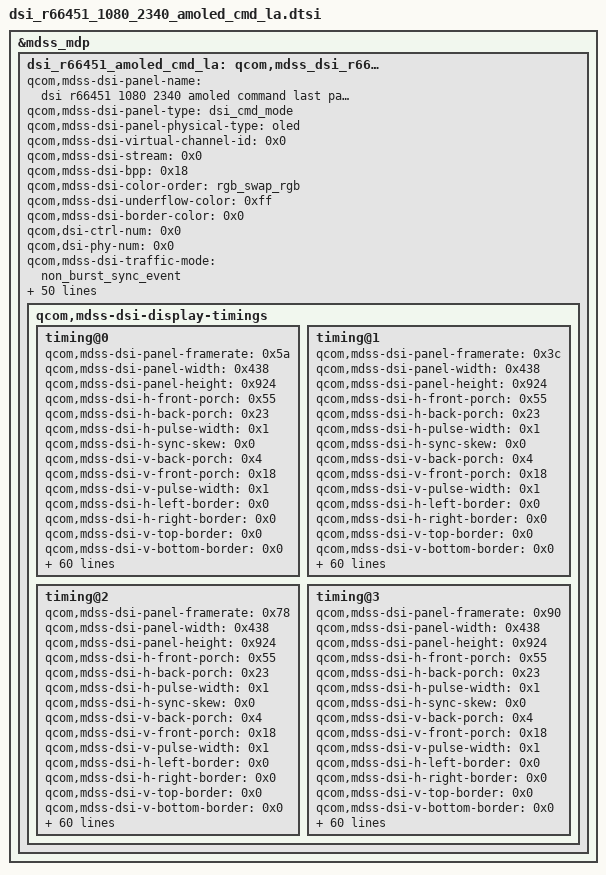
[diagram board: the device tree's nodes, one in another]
/* Copyright (c) 2020, Nubia Technology Co., Ltd. All rights reserved.
 *
 * 从官方 NX651J boot.img 的 dtb 区反编译还原。
 * 这是 "last panel"（末版面板）配置，开源包 dts 中缺失。
 * 官方 release 的 lito/orchid overlay 均包含此节点（每个 +13149 字节）：
 *   官方 dtbo #14 lito-v2-mtp = 281693 字节 vs 开源包 268544 字节
 */

&mdss_mdp {
	dsi_r66451_amoled_cmd_la: qcom,mdss_dsi_r66451_1080_2340_amoled_cmd_la {
		qcom,mdss-dsi-panel-name = "dsi r66451 1080 2340 amoled command last panel";
		qcom,mdss-dsi-panel-type = "dsi_cmd_mode";
		qcom,mdss-dsi-panel-physical-type = "oled";
		qcom,mdss-dsi-virtual-channel-id = <0x0>;
		qcom,mdss-dsi-stream = <0x0>;
		qcom,mdss-dsi-bpp = <0x18>;
		qcom,mdss-dsi-color-order = "rgb_swap_rgb";
		qcom,mdss-dsi-underflow-color = <0xff>;
		qcom,mdss-dsi-border-color = <0x0>;
		qcom,dsi-ctrl-num = <0x0>;
		qcom,dsi-phy-num = <0x0>;
		qcom,mdss-dsi-traffic-mode = "non_burst_sync_event";
		qcom,mdss-dsi-lane-map = "lane_map_0123";
		qcom,mdss-dsi-bllp-eof-power-mode;
		qcom,mdss-dsi-bllp-power-mode;
		qcom,mdss-dsi-lane-0-state;
		qcom,mdss-dsi-lane-1-state;
		qcom,mdss-dsi-lane-2-state;
		qcom,mdss-dsi-lane-3-state;
		qcom,mdss-dsi-dma-trigger = "trigger_sw";
		qcom,mdss-dsi-mdp-trigger = "none";
		qcom,mdss-dsi-reset-sequence = <0x1 0xa 0x0 0xa 0x1 0xa>;
		qcom,mdss-dsi-bl-pmic-control-type = "bl_ctrl_dcs";
		qcom,mdss-dsi-bl-min-level = <0x2d>;
		qcom,mdss-dsi-bl-max-level = <0xfff>;
		qcom,mdss-brightness-max-level = <0xfff>;
		qcom,mdss-dsi-te-pin-select = <0x1>;
		qcom,mdss-dsi-wr-mem-start = <0x2c>;
		qcom,mdss-dsi-wr-mem-continue = <0x3c>;
		qcom,panel-supply-entries = <&dsi_panel_pwr_supply>;
		qcom,platform-te-gpio = <&tlmm 10 0>;
		qcom,platform-reset-gpio = <&pm8150l_gpios 3 0>;
		qcom,panel-lhbm-gpio = <&tlmm 55 0>;
		qcom,mdss-dsi-te-dcs-command = <0x1>;
		qcom,mdss-dsi-te-check-enable;
		qcom,mdss-dsi-te-using-te-pin;
		qcom,mdss-dsi-t-clk-post = <0x17>;
		qcom,mdss-dsi-t-clk-pre = <0x18>;
		qcom,mdss-dsi-panel-hdr-enabled;
		qcom,mdss-dsi-panel-hdr-color-primaries = <0x38a4 0x3c8c 0x7d00 0x4268 0x3c8c 0x7530 0x1f40 0xbb8>;
		qcom,mdss-dsi-panel-peak-brightness = <0x401640>;
		qcom,mdss-dsi-panel-blackness-level = <0xc9e>;
		qcom,mdss-dsi-qsync-min-refresh-rate = <0x37>;
		qcom,mdss-pan-physical-width-dimension = <0x48>;
		qcom,mdss-pan-physical-height-dimension = <0x9c>;
		qcom,esd-check-enabled;
		qcom,mdss-dsi-panel-status-check-mode = "reg_read";
		qcom,mdss-dsi-panel-status-command = <0x6010001 0x500010a 0x6010001 0x50001f9 0x6010001 0x50001f8>;
		qcom,mdss-dsi-panel-status-command-state = "dsi_hs_mode";
		qcom,mdss-dsi-panel-status-value = <0x1c 0x0 0x11 0x0 0x0 0x89 0x30 0x80 0x9 0x24 0x4 0x38>;
		qcom,mdss-dsi-panel-status-read-length = <0x1 0x1 0xa>;
		qcom,dsi-select-clocks = "mux_byte_clk0", "mux_pixel_clk0";

		qcom,mdss-dsi-display-timings {

			timing@0 {
				qcom,mdss-dsi-panel-framerate = <0x5a>;
				qcom,mdss-dsi-panel-width = <0x438>;
				qcom,mdss-dsi-panel-height = <0x924>;
				qcom,mdss-dsi-h-front-porch = <0x55>;
				qcom,mdss-dsi-h-back-porch = <0x23>;
				qcom,mdss-dsi-h-pulse-width = <0x1>;
				qcom,mdss-dsi-h-sync-skew = <0x0>;
				qcom,mdss-dsi-v-back-porch = <0x4>;
				qcom,mdss-dsi-v-front-porch = <0x18>;
				qcom,mdss-dsi-v-pulse-width = <0x1>;
				qcom,mdss-dsi-h-left-border = <0x0>;
				qcom,mdss-dsi-h-right-border = <0x0>;
				qcom,mdss-dsi-v-top-border = <0x0>;
				qcom,mdss-dsi-v-bottom-border = <0x0>;
				qcom,mdss-mdp-transfer-time-us = <0x1f40>;
				qcom,mdss-dsi-panel-jitter = <0x3c 0xa>;
				qcom,mdss-dsi-on-command = [39 01 00 00 00 00 02 b0 00 39 01 00 00 00 00 02 d1 0b 39 01 00 00 00 00 0c c2 09 24 0c 00 00 10 00 00 00 09 40 39 01 00 00 00 00 2c c4 00 00 00 00 00 00 00 00 0d 00 00 05 00 00 00 36 00 01 00 00 00 00 00 00 00 00 00 00 00 22 00 00 00 00 11 00 00 0c 00 00 00 00 30 39 01 00 00 00 00 02 f1 4d 39 01 00 00 00 00 02 cf 13 39 01 00 00 00 00 0d d0 44 44 b2 28 00 28 5a 00 5a 0d 17 01 39 01 00 00 00 00 15 d3 45 00 00 01 b0 15 00 15 07 0f 77 77 77 37 b2 11 00 a0 3c a1 39 01 00 00 00 00 1a d7 00 b9 40 00 40 00 00 e0 0e 00 40 00 00 00 00 00 00 19 40 00 00 00 00 e0 0e 39 01 00 00 00 00 34 d8 00 00 00 00 00 00 00 00 00 3c 00 3c 00 3c 00 3c 00 3c 05 00 00 00 00 00 00 00 00 00 0e 00 0e 00 00 00 00 00 00 00 00 00 00 00 00 00 0e 00 36 00 0e 00 30 39 01 00 00 00 00 2b df 50 42 58 81 2d 00 00 00 00 00 00 6b 00 00 00 00 00 00 00 00 21 00 ff d4 0e 00 00 00 00 00 20 00 53 18 20 00 00 00 00 00 00 00 39 01 00 00 00 00 02 f7 01 39 01 00 00 00 00 02 fa 0b 39 01 00 00 00 00 02 f1 02 39 01 00 00 00 00 09 c7 00 04 00 00 00 20 00 00 39 01 00 00 00 00 02 f1 32 39 01 00 00 00 00 09 c7 00 04 00 00 00 20 00 00 39 01 00 00 00 00 02 f1 62 39 01 00 00 00 00 09 c7 00 04 00 00 00 20 00 00 39 01 00 00 00 00 02 b0 80 39 01 00 00 00 00 02 f1 24 39 01 00 00 00 00 03 df 51 50 39 01 00 00 00 00 0a e4 34 b4 00 00 00 3b 08 04 9a 39 01 00 00 00 00 02 e6 00 39 01 00 00 00 00 02 b0 04 39 01 00 00 00 00 03 df 50 40 39 01 00 00 00 00 06 f3 50 00 00 00 00 39 01 00 00 00 00 02 f2 11 39 01 00 00 00 00 06 f3 01 00 00 00 01 39 01 00 00 00 00 03 f4 00 02 39 01 00 00 00 00 02 f2 19 39 01 00 00 00 00 03 df 50 42 39 01 00 00 00 00 02 35 00 39 01 00 00 00 00 05 2a 00 00 04 37 39 01 00 00 00 00 05 2b 00 00 09 23 05 01 00 00 8c 00 02 11 00 05 01 00 00 14 00 02 29 00];
				qcom,mdss-dsi-timing-switch-command = [39 01 00 00 00 00 02 b0 00 39 01 00 00 00 00 02 d1 0b 39 01 00 00 00 00 0c c2 09 24 0c 00 00 10 00 00 00 09 40 39 01 00 00 00 00 2c c4 00 00 00 00 00 00 00 00 0d 00 00 05 00 00 00 36 00 01 00 00 00 00 00 00 00 00 00 00 00 22 00 00 00 00 11 00 00 0c 00 00 00 00 30 39 01 00 00 00 00 02 f1 4d 39 01 00 00 00 00 02 cf 13 39 01 00 00 00 00 0d d0 44 44 b2 28 00 28 5a 00 5a 0d 17 01 39 01 00 00 00 00 15 d3 45 00 00 01 b0 15 00 15 07 0f 77 77 77 37 b2 11 00 a0 3c a1 39 01 00 00 00 00 1a d7 00 b9 40 00 40 00 00 e0 0e 00 40 00 00 00 00 00 00 19 40 00 00 00 00 e0 0e 39 01 00 00 00 00 34 d8 00 00 00 00 00 00 00 00 00 3c 00 3c 00 3c 00 3c 00 3c 05 00 00 00 00 00 00 00 00 00 0e 00 0e 00 00 00 00 00 00 00 00 00 00 00 00 00 0e 00 36 00 0e 00 30 39 01 00 00 00 00 02 f7 01 39 01 00 00 00 00 02 fa 0b 39 01 00 00 00 00 02 f1 02 39 01 00 00 00 00 09 c7 00 04 00 00 00 20 00 00 39 01 00 00 00 00 02 f1 32 39 01 00 00 00 00 09 c7 00 04 00 00 00 20 00 00 39 01 00 00 00 00 02 f1 62 39 01 00 00 00 00 09 c7 00 04 00 00 00 20 00 00 39 01 00 00 00 00 02 b0 80 39 01 00 00 00 00 02 f1 24 39 01 00 00 00 00 03 df 51 50 39 01 00 00 00 00 0a e4 34 b4 00 00 00 3b 08 04 9a 39 01 00 00 00 00 02 e6 00 39 01 00 00 00 00 02 b0 04 39 01 00 00 00 00 03 df 50 40 39 01 00 00 00 00 06 f3 50 00 00 00 00 39 01 00 00 00 00 02 f2 11 39 01 00 00 00 00 06 f3 01 00 00 00 01 39 01 00 00 00 00 03 f4 00 02 39 01 00 00 00 00 02 f2 19 39 01 00 00 00 00 03 df 50 42 39 01 00 00 00 00 02 35 00 39 01 00 00 00 00 05 2a 00 00 04 37 39 01 00 00 00 00 05 2b 00 00 09 23];
				qcom,mdss-dsi-off-command = [05 01 00 00 64 00 02 28 00 05 01 00 00 32 00 02 10 00];
				qcom,mdss-dsi-on-command-state = "dsi_lp_mode";
				qcom,mdss-dsi-off-command-state = "dsi_hs_mode";
				nubia,mdss-dsi-cabc-command-off = [15 01 00 00 00 00 02 55 00];
				nubia,mdss-dsi-cabc-command-level1 = [15 01 00 00 00 00 02 55 01];
				nubia,mdss-dsi-cabc-command-level2 = [15 01 00 00 00 00 02 55 02];
				nubia,mdss-dsi-cabc-command-level3 = [15 01 00 00 00 00 02 55 03];
				nubia,mdss-dsi-cabc-command-off-state = "dsi_hs_mode";
				nubia,mdss-dsi-cabc-command-level1-state = "dsi_hs_mode";
				nubia,mdss-dsi-cabc-command-level2-state = "dsi_hs_mode";
				nubia,mdss-dsi-cabc-command-level3-state = "dsi_hs_mode";
				qcom,mdss-dsi-nolp-command = <0x39010000 0x2b0 0x80390100 0x2 0xdfb43901 0x0 0x2530439 0x1000050 0x35100 0x390100 0x2 0x38003901 0x0 0x2b00439 0x1000064 0xcc209 0x240c0000 0x10094000 0x9403901 0x0 0xcc20924 0xc000010 0x9 0x40390100 0x4a 0xc1944200 0x16050000 0x100010 0xaa8a02 0x10001000 0x3f3f03 0xff03ff23 0xff03ff23 0xff03ff00 0x40400000 0x10060006 0x10 0x0 0x10000000 0x100000 0x20021001 0x10000000 0x2004 0x20023901 0x0 0x33d34500 0x11315 0x15070f 0x77777737 0xb21100a0 0x3c95003e 0x6a106010 0x1037307 0xff044433 0x33830400 0x0 0x3c00 0x7e7e7e00 0x39010000 0x1ad7 0xb94000 0x400000e0 0xe004000 0x0 0x194000 0xe0 0xe390100 0x34 0xd8000000 0x0 0x3c00 0x3c003c00 0x3c003c05 0x0 0x0 0xe000e 0x0 0x0 0x0 0xe0036 0xe0030>;
				qcom,mdss-dsi-lp1-command = [39 01 00 00 14 00 02 53 04 39 01 00 00 00 00 02 b0 80 39 01 00 00 14 00 02 df b4 39 01 00 00 00 00 02 39 00 39 01 00 00 00 00 02 b0 04 39 01 00 00 00 00 03 e8 00 02 39 01 00 00 00 00 03 e4 00 34 39 01 00 00 00 00 02 b0 04 39 01 00 00 00 00 7d c1 d4 42 00 3f 0f 00 00 00 10 00 10 00 aa 8a 02 10 00 10 00 00 3f 3f 03 ff 03 ff 23 ff 03 ff 23 ff 03 ff f0 40 40 00 00 10 06 00 06 00 00 00 10 00 00 00 00 10 00 00 00 00 10 00 00 20 02 10 01 10 00 00 00 00 00 20 04 20 03 10 00 00 00 00 00 00 00 10 00 00 00 00 00 00 00 00 00 10 00 00 00 00 00 00 00 00 00 00 00 00 00 00 00 00 00 00 00 00 00 00 00 00 00 00 00 00 00 00 00 00 39 01 00 00 00 00 35 d3 45 00 00 01 13 15 00 15 07 0f 77 77 77 37 b2 11 00 a0 3c 9c 00 3e 6a 10 60 10 01 03 73 01 11 01 11 33 33 83 04 00 00 00 00 00 00 00 3c 00 7e 7e 7e 03 42 01 39 01 00 00 00 00 1a d7 00 b9 40 00 40 00 02 c0 2c 00 40 00 00 00 00 00 00 19 40 00 00 00 02 c0 2c 39 01 00 00 00 00 3c d8 00 00 00 00 00 00 00 00 00 5b 00 5b 00 5b 00 5b 00 5b 05 00 00 00 00 00 00 00 00 00 2c 00 2c 00 00 00 00 00 00 00 00 00 00 00 00 00 2c 00 6d 00 2c 00 0c 00 00 00 00 00 00 00 00];
				qcom,mdss-dsi-nolp-command-state = "dsi_hs_mode";
				qcom,mdss-dsi-lp1-command-state = "dsi_hs_mode";
				nubia,mdss-dsi-hbm-command-on = [39 01 00 00 00 00 02 b0 00 15 01 00 00 00 00 02 53 e8];
				nubia,mdss-dsi-hbm-command-off = [39 01 00 00 00 00 02 b0 00 15 01 00 00 00 00 02 53 00];
				nubia,mdss-dsi-hbm-fp-command-on = [39 01 00 00 00 00 02 b0 00 15 01 00 00 00 00 02 53 e0];
				nubia,mdss-dsi-hbm-fp-command-off = [39 01 00 00 00 00 02 b0 00 15 01 00 00 00 00 02 53 00];
				nubia,mdss-dsi-hbm-command-on-state = "dsi_hs_mode";
				nubia,mdss-dsi-hbm-command-off-state = "dsi_hs_mode";
				nubia,mdss-dsi-hbm-fp-command-on-state = "dsi_hs_mode";
				nubia,mdss-dsi-hbm-fp-command-off-state = "dsi_hs_mode";
				qcom,mdss-dsi-h-sync-pulse = <0x0>;
				qcom,compression-mode = "dsc";
				qcom,mdss-dsc-slice-height = <0x14>;
				qcom,mdss-dsc-slice-width = <0x21c>;
				qcom,mdss-dsc-slice-per-pkt = <0x2>;
				qcom,mdss-dsc-bit-per-component = <0x8>;
				qcom,mdss-dsc-bit-per-pixel = <0x8>;
				qcom,mdss-dsc-block-prediction-enable;
				qcom,mdss-dsi-panel-phy-timings = [00 17 05 05 20 1f 06 06 03 02 04 00 13 15];
				qcom,display-topology = <0x1 0x1 0x1>;
				qcom,default-topology-index = <0x0>;
			};

			timing@1 {
				qcom,mdss-dsi-panel-framerate = <0x3c>;
				qcom,mdss-dsi-panel-width = <0x438>;
				qcom,mdss-dsi-panel-height = <0x924>;
				qcom,mdss-dsi-h-front-porch = <0x55>;
				qcom,mdss-dsi-h-back-porch = <0x23>;
				qcom,mdss-dsi-h-pulse-width = <0x1>;
				qcom,mdss-dsi-h-sync-skew = <0x0>;
				qcom,mdss-dsi-v-back-porch = <0x4>;
				qcom,mdss-dsi-v-front-porch = <0x18>;
				qcom,mdss-dsi-v-pulse-width = <0x1>;
				qcom,mdss-dsi-h-left-border = <0x0>;
				qcom,mdss-dsi-h-right-border = <0x0>;
				qcom,mdss-dsi-v-top-border = <0x0>;
				qcom,mdss-dsi-v-bottom-border = <0x0>;
				qcom,mdss-mdp-transfer-time-us = <0x30d4>;
				qcom,mdss-dsi-panel-jitter = <0x3c 0xa>;
				qcom,mdss-dsi-on-command = [39 01 00 00 00 00 02 b0 00 39 01 00 00 00 00 02 d1 0b 39 01 00 00 00 00 0c c2 09 24 0c 00 00 10 04 a0 00 09 40 39 01 00 00 00 00 2c c4 00 00 00 00 00 00 00 00 0d 00 00 05 00 00 00 36 00 01 00 00 00 00 00 00 00 00 00 00 00 22 00 00 00 00 11 00 00 0c 00 00 00 00 30 39 01 00 00 00 00 02 f1 4d 39 01 00 00 00 00 02 cf 13 39 01 00 00 00 00 0d d0 44 44 b2 28 00 28 5a 00 5a 0d 17 01 39 01 00 00 00 00 15 d3 45 00 00 01 b0 15 00 15 07 0f 77 77 77 37 b2 11 00 a0 3c a1 39 01 00 00 00 00 1a d7 00 b9 40 00 40 00 00 e0 0e 00 40 00 00 00 00 00 00 19 40 00 00 00 00 e0 0e 39 01 00 00 00 00 34 d8 00 00 00 00 00 00 00 00 00 3c 00 3c 00 3c 00 3c 00 3c 05 00 00 00 00 00 00 00 00 00 0e 00 0e 00 00 00 00 00 00 00 00 00 00 00 00 00 0e 00 36 00 0e 00 30 39 01 00 00 00 00 2b df 50 42 58 81 2d 00 00 00 00 00 00 6b 00 00 00 00 00 00 00 00 21 00 ff d4 0e 00 00 00 00 00 20 00 53 18 20 00 00 00 00 00 00 00 39 01 00 00 00 00 02 f7 01 39 01 00 00 00 00 02 fa 0b 39 01 00 00 00 00 02 f1 02 39 01 00 00 00 00 09 c7 00 04 00 00 00 20 00 00 39 01 00 00 00 00 02 f1 32 39 01 00 00 00 00 09 c7 00 04 00 00 00 20 00 00 39 01 00 00 00 00 02 f1 62 39 01 00 00 00 00 09 c7 00 04 00 00 00 20 00 00 39 01 00 00 00 00 02 b0 80 39 01 00 00 00 00 02 f1 24 39 01 00 00 00 00 03 df 51 50 39 01 00 00 00 00 0a e4 34 b4 00 00 00 3b 08 04 9a 39 01 00 00 00 00 02 e6 00 39 01 00 00 00 00 02 b0 04 39 01 00 00 00 00 03 df 50 40 39 01 00 00 00 00 06 f3 50 00 00 00 00 39 01 00 00 00 00 02 f2 11 39 01 00 00 00 00 06 f3 01 00 00 00 01 39 01 00 00 00 00 03 f4 00 02 39 01 00 00 00 00 02 f2 19 39 01 00 00 00 00 03 df 50 42 39 01 00 00 00 00 02 35 00 39 01 00 00 00 00 05 2a 00 00 04 37 39 01 00 00 00 00 05 2b 00 00 09 23 05 01 00 00 8c 00 02 11 00 05 01 00 00 14 00 02 29 00];
				qcom,mdss-dsi-timing-switch-command = [39 01 00 00 00 00 02 b0 00 39 01 00 00 00 00 02 d1 0b 39 01 00 00 00 00 0c c2 09 24 0c 00 00 10 04 a0 00 09 40 39 01 00 00 00 00 2c c4 00 00 00 00 00 00 00 00 0d 00 00 05 00 00 00 36 00 01 00 00 00 00 00 00 00 00 00 00 00 22 00 00 00 00 11 00 00 0c 00 00 00 00 30 39 01 00 00 00 00 02 f1 4d 39 01 00 00 00 00 02 cf 13 39 01 00 00 00 00 0d d0 44 44 b2 28 00 28 5a 00 5a 0d 17 01 39 01 00 00 00 00 15 d3 45 00 00 01 b0 15 00 15 07 0f 77 77 77 37 b2 11 00 a0 3c a1 39 01 00 00 00 00 1a d7 00 b9 40 00 40 00 00 e0 0e 00 40 00 00 00 00 00 00 19 40 00 00 00 00 e0 0e 39 01 00 00 00 00 34 d8 00 00 00 00 00 00 00 00 00 3c 00 3c 00 3c 00 3c 00 3c 05 00 00 00 00 00 00 00 00 00 0e 00 0e 00 00 00 00 00 00 00 00 00 00 00 00 00 0e 00 36 00 0e 00 30 39 01 00 00 00 00 02 f7 01 39 01 00 00 00 00 02 fa 0b 39 01 00 00 00 00 02 f1 02 39 01 00 00 00 00 09 c7 00 04 00 00 00 20 00 00 39 01 00 00 00 00 02 f1 32 39 01 00 00 00 00 09 c7 00 04 00 00 00 20 00 00 39 01 00 00 00 00 02 f1 62 39 01 00 00 00 00 09 c7 00 04 00 00 00 20 00 00 39 01 00 00 00 00 02 b0 80 39 01 00 00 00 00 02 f1 24 39 01 00 00 00 00 03 df 51 50 39 01 00 00 00 00 0a e4 34 b4 00 00 00 3b 08 04 9a 39 01 00 00 00 00 02 e6 00 39 01 00 00 00 00 02 b0 04 39 01 00 00 00 00 03 df 50 40 39 01 00 00 00 00 06 f3 50 00 00 00 00 39 01 00 00 00 00 02 f2 11 39 01 00 00 00 00 06 f3 01 00 00 00 01 39 01 00 00 00 00 03 f4 00 02 39 01 00 00 00 00 02 f2 19 39 01 00 00 00 00 03 df 50 42 39 01 00 00 00 00 02 35 00 39 01 00 00 00 00 05 2a 00 00 04 37 39 01 00 00 14 00 05 2b 00 00 09 23];
				qcom,mdss-dsi-off-command = [05 01 00 00 64 00 02 28 00 05 01 00 00 32 00 02 10 00];
				qcom,mdss-dsi-on-command-state = "dsi_lp_mode";
				qcom,mdss-dsi-off-command-state = "dsi_hs_mode";
				nubia,mdss-dsi-cabc-command-off = [15 01 00 00 00 00 02 55 00];
				nubia,mdss-dsi-cabc-command-level1 = [15 01 00 00 00 00 02 55 01];
				nubia,mdss-dsi-cabc-command-level2 = [15 01 00 00 00 00 02 55 02];
				nubia,mdss-dsi-cabc-command-level3 = [15 01 00 00 00 00 02 55 03];
				nubia,mdss-dsi-cabc-command-off-state = "dsi_hs_mode";
				nubia,mdss-dsi-cabc-command-level1-state = "dsi_hs_mode";
				nubia,mdss-dsi-cabc-command-level2-state = "dsi_hs_mode";
				nubia,mdss-dsi-cabc-command-level3-state = "dsi_hs_mode";
				qcom,mdss-dsi-nolp-command = [39 01 00 00 00 00 02 b0 80 39 01 00 00 00 00 02 df b4 39 01 00 00 00 00 02 53 04 39 01 00 00 50 00 03 51 00 00 39 01 00 00 00 00 02 38 00 39 01 00 00 00 00 02 b0 04 39 01 00 00 64 00 0c c2 09 24 0c 00 00 10 09 40 00 09 40 39 01 00 00 00 00 0c c2 09 24 0c 00 00 10 04 a0 00 09 40 39 01 00 00 00 00 4a c1 94 42 00 16 05 00 00 00 10 00 10 00 aa 8a 02 10 00 10 00 00 3f 3f 03 ff 03 ff 23 ff 03 ff 23 ff 03 ff 00 40 40 00 00 10 06 00 06 00 00 00 10 00 00 00 00 10 00 00 00 00 10 00 00 20 02 10 01 10 00 00 00 00 00 20 04 20 02 39 01 00 00 00 00 35 d3 45 00 00 01 13 15 00 15 07 0f 77 77 77 37 b2 11 00 a0 3c 95 00 3e 6a 10 60 10 01 03 73 07 ff 04 44 33 33 83 04 00 00 00 00 00 00 00 3c 00 7e 7e 7e 00 42 01 39 01 00 00 00 00 1a d7 00 b9 40 00 40 00 00 e0 0e 00 40 00 00 00 00 00 00 19 40 00 00 00 00 e0 0e 39 01 00 00 00 00 3c d8 00 00 00 00 00 00 00 00 00 3c 00 3c 00 3c 00 3c 00 3c 05 00 00 00 00 00 00 00 00 00 0e 00 0e 00 00 00 00 00 00 00 00 00 00 00 00 00 0e 00 36 00 0e 00 30 00 00 00 00 00 00 00 00];
				qcom,mdss-dsi-lp1-command = [39 01 00 00 14 00 02 53 04 39 01 00 00 00 00 02 b0 80 39 01 00 00 14 00 02 df b4 39 01 00 00 00 00 02 39 00 39 01 00 00 00 00 02 b0 04 39 01 00 00 00 00 03 e8 00 02 39 01 00 00 00 00 03 e4 00 34 39 01 00 00 00 00 02 b0 04 39 01 00 00 00 00 7d c1 d4 42 00 3f 0f 00 00 00 10 00 10 00 aa 8a 02 10 00 10 00 00 3f 3f 03 ff 03 ff 23 ff 03 ff 23 ff 03 ff f0 40 40 00 00 10 06 00 06 00 00 00 10 00 00 00 00 10 00 00 00 00 10 00 00 20 02 10 01 10 00 00 00 00 00 20 04 20 03 10 00 00 00 00 00 00 00 10 00 00 00 00 00 00 00 00 00 10 00 00 00 00 00 00 00 00 00 00 00 00 00 00 00 00 00 00 00 00 00 00 00 00 00 00 00 00 00 00 00 00 39 01 00 00 00 00 35 d3 45 00 00 01 13 15 00 15 07 0f 77 77 77 37 b2 11 00 a0 3c 9c 00 3e 6a 10 60 10 01 03 73 01 11 01 11 33 33 83 04 00 00 00 00 00 00 00 3c 00 7e 7e 7e 03 42 01 39 01 00 00 00 00 1a d7 00 b9 40 00 40 00 02 c0 2c 00 40 00 00 00 00 00 00 19 40 00 00 00 02 c0 2c 39 01 00 00 00 00 3c d8 00 00 00 00 00 00 00 00 00 5b 00 5b 00 5b 00 5b 00 5b 05 00 00 00 00 00 00 00 00 00 2c 00 2c 00 00 00 00 00 00 00 00 00 00 00 00 00 2c 00 6d 00 2c 00 0c 00 00 00 00 00 00 00 00];
				qcom,mdss-dsi-nolp-command-state = "dsi_hs_mode";
				qcom,mdss-dsi-lp1-command-state = "dsi_hs_mode";
				nubia,mdss-dsi-hbm-command-on = [39 01 00 00 00 00 02 b0 00 15 01 00 00 00 00 02 53 e8];
				nubia,mdss-dsi-hbm-command-off = [39 01 00 00 00 00 02 b0 00 15 01 00 00 00 00 02 53 00];
				nubia,mdss-dsi-hbm-fp-command-on = [39 01 00 00 00 00 02 b0 00 15 01 00 00 00 00 02 53 e0];
				nubia,mdss-dsi-hbm-fp-command-off = [39 01 00 00 00 00 02 b0 00 15 01 00 00 00 00 02 53 00];
				nubia,mdss-dsi-hbm-command-on-state = "dsi_hs_mode";
				nubia,mdss-dsi-hbm-command-off-state = "dsi_hs_mode";
				nubia,mdss-dsi-hbm-fp-command-on-state = "dsi_hs_mode";
				nubia,mdss-dsi-hbm-fp-command-off-state = "dsi_hs_mode";
				qcom,mdss-dsi-h-sync-pulse = <0x0>;
				qcom,compression-mode = "dsc";
				qcom,mdss-dsc-slice-height = <0x14>;
				qcom,mdss-dsc-slice-width = <0x21c>;
				qcom,mdss-dsc-slice-per-pkt = <0x2>;
				qcom,mdss-dsc-bit-per-component = <0x8>;
				qcom,mdss-dsc-bit-per-pixel = <0x8>;
				qcom,mdss-dsc-block-prediction-enable;
				qcom,mdss-dsi-panel-phy-timings = [00 11 03 04 1e 1e 04 04 02 02 04 00 10 14];
				qcom,display-topology = <0x1 0x1 0x1>;
				qcom,default-topology-index = <0x0>;
			};

			timing@2 {
				qcom,mdss-dsi-panel-framerate = <0x78>;
				qcom,mdss-dsi-panel-width = <0x438>;
				qcom,mdss-dsi-panel-height = <0x924>;
				qcom,mdss-dsi-h-front-porch = <0x55>;
				qcom,mdss-dsi-h-back-porch = <0x23>;
				qcom,mdss-dsi-h-pulse-width = <0x1>;
				qcom,mdss-dsi-h-sync-skew = <0x0>;
				qcom,mdss-dsi-v-back-porch = <0x4>;
				qcom,mdss-dsi-v-front-porch = <0x18>;
				qcom,mdss-dsi-v-pulse-width = <0x1>;
				qcom,mdss-dsi-h-left-border = <0x0>;
				qcom,mdss-dsi-h-right-border = <0x0>;
				qcom,mdss-dsi-v-top-border = <0x0>;
				qcom,mdss-dsi-v-bottom-border = <0x0>;
				qcom,mdss-mdp-transfer-time-us = <0x1c84>;
				qcom,mdss-dsi-panel-jitter = <0x3c 0xa>;
				qcom,mdss-dsi-on-command = [39 01 00 00 00 00 02 b0 00 39 01 00 00 00 00 02 d1 0b 39 01 00 00 00 00 0c c2 09 24 0c 00 00 10 00 00 00 09 40 39 01 00 00 00 00 2c c4 00 00 00 00 00 00 00 00 10 00 00 02 00 00 00 29 00 01 00 00 00 00 00 00 00 00 00 00 00 22 00 00 00 00 11 00 00 0c 00 00 00 00 30 39 01 00 00 00 00 02 f1 4d 39 01 00 00 00 00 02 cf 13 39 01 00 00 00 00 0d d0 44 44 b2 28 00 28 5a 00 5a 0d 17 01 39 01 00 00 00 00 15 d3 49 00 00 01 b0 15 00 15 07 0f 77 77 77 37 b2 11 00 a0 3c a1 39 01 00 00 00 00 1a d7 00 b9 40 00 40 04 00 f0 0f 00 40 00 00 00 00 00 00 19 40 00 40 04 00 f0 0f 39 01 00 00 00 00 34 d8 00 00 00 00 00 00 00 00 00 3a 00 3a 00 3a 00 3a 00 3a 05 00 00 00 00 00 00 00 00 00 0f 00 0f 00 00 00 00 00 00 00 00 00 00 00 00 00 0f 00 2f 00 0f 00 20 39 01 00 00 00 00 2b df 50 42 58 81 2d 00 00 00 00 00 00 6b 00 00 00 00 00 00 00 00 01 0f ff d4 0e 00 00 00 00 00 00 0f 53 18 00 0f 00 00 00 00 00 00 39 01 00 00 00 00 02 f7 01 39 01 00 00 00 00 02 fa 0b 39 01 00 00 00 00 02 f1 02 39 01 00 00 00 00 09 c7 00 04 00 00 00 20 00 00 39 01 00 00 00 00 02 f1 32 39 01 00 00 00 00 09 c7 00 04 00 00 00 20 00 00 39 01 00 00 00 00 02 f1 62 39 01 00 00 00 00 09 c7 00 04 00 00 00 20 00 00 39 01 00 00 00 00 02 b0 80 39 01 00 00 00 00 02 f1 24 39 01 00 00 00 00 03 df 51 50 39 01 00 00 00 00 0a e4 34 b4 00 00 00 30 04 0c e2 39 01 00 00 00 00 02 e6 00 39 01 00 00 00 00 02 b0 04 39 01 00 00 00 00 03 df 50 40 39 01 00 00 00 00 06 f3 50 00 00 00 00 39 01 00 00 00 00 02 f2 11 39 01 00 00 00 00 06 f3 01 00 00 00 01 39 01 00 00 00 00 03 f4 00 02 39 01 00 00 00 00 02 f2 19 39 01 00 00 00 00 03 df 50 42 39 01 00 00 00 00 02 35 00 39 01 00 00 00 00 05 2a 00 00 04 37 39 01 00 00 00 00 05 2b 00 00 09 23 05 01 00 00 8c 00 02 11 00 05 01 00 00 14 00 02 29 00];
				qcom,mdss-dsi-timing-switch-command = [39 01 00 00 00 00 02 b0 00 39 01 00 00 00 00 02 d1 0b 39 01 00 00 00 00 0c c2 09 24 0c 00 00 10 00 00 00 09 40 39 01 00 00 00 00 2c c4 00 00 00 00 00 00 00 00 10 00 00 02 00 00 00 29 00 01 00 00 00 00 00 00 00 00 00 00 00 22 00 00 00 00 11 00 00 0c 00 00 00 00 30 39 01 00 00 00 00 02 f1 4d 39 01 00 00 00 00 02 cf 13 39 01 00 00 00 00 0d d0 44 44 b2 28 00 28 5a 00 5a 0d 17 01 39 01 00 00 00 00 15 d3 49 00 00 01 b0 15 00 15 07 0f 77 77 77 37 b2 11 00 a0 3c a1 39 01 00 00 00 00 1a d7 00 b9 40 00 40 04 00 f0 0f 00 40 00 00 00 00 00 00 19 40 00 40 04 00 f0 0f 39 01 00 00 00 00 34 d8 00 00 00 00 00 00 00 00 00 3a 00 3a 00 3a 00 3a 00 3a 05 00 00 00 00 00 00 00 00 00 0f 00 0f 00 00 00 00 00 00 00 00 00 00 00 00 00 0f 00 2f 00 0f 00 20 39 01 00 00 00 00 02 f7 01 39 01 00 00 00 00 02 fa 0b 39 01 00 00 00 00 02 f1 02 39 01 00 00 00 00 09 c7 00 04 00 00 00 20 00 00 39 01 00 00 00 00 02 f1 32 39 01 00 00 00 00 09 c7 00 04 00 00 00 20 00 00 39 01 00 00 00 00 02 f1 62 39 01 00 00 00 00 09 c7 00 04 00 00 00 20 00 00 39 01 00 00 00 00 02 b0 80 39 01 00 00 00 00 02 f1 24 39 01 00 00 00 00 03 df 51 50 39 01 00 00 00 00 0a e4 34 b4 00 00 00 30 04 0c e2 39 01 00 00 00 00 02 e6 00 39 01 00 00 00 00 02 b0 04 39 01 00 00 00 00 03 df 50 40 39 01 00 00 00 00 06 f3 50 00 00 00 00 39 01 00 00 00 00 02 f2 11 39 01 00 00 00 00 06 f3 01 00 00 00 01 39 01 00 00 00 00 03 f4 00 02 39 01 00 00 00 00 02 f2 19 39 01 00 00 00 00 03 df 50 42 39 01 00 00 00 00 02 35 00 39 01 00 00 00 00 05 2a 00 00 04 37 39 01 00 00 00 00 05 2b 00 00 09 23];
				qcom,mdss-dsi-off-command = [05 01 00 00 64 00 02 28 00 05 01 00 00 32 00 02 10 00];
				qcom,mdss-dsi-on-command-state = "dsi_lp_mode";
				qcom,mdss-dsi-off-command-state = "dsi_hs_mode";
				nubia,mdss-dsi-cabc-command-off = [15 01 00 00 00 00 02 55 00];
				nubia,mdss-dsi-cabc-command-level1 = [15 01 00 00 00 00 02 55 01];
				nubia,mdss-dsi-cabc-command-level2 = [15 01 00 00 00 00 02 55 02];
				nubia,mdss-dsi-cabc-command-level3 = [15 01 00 00 00 00 02 55 03];
				nubia,mdss-dsi-cabc-command-off-state = "dsi_hs_mode";
				nubia,mdss-dsi-cabc-command-level1-state = "dsi_hs_mode";
				nubia,mdss-dsi-cabc-command-level2-state = "dsi_hs_mode";
				nubia,mdss-dsi-cabc-command-level3-state = "dsi_hs_mode";
				qcom,mdss-dsi-nolp-command = [39 01 00 00 00 00 02 b0 80 39 01 00 00 00 00 02 df b4 39 01 00 00 00 00 02 53 04 39 01 00 00 50 00 03 51 00 00 39 01 00 00 00 00 02 38 00 39 01 00 00 00 00 02 b0 04 39 01 00 00 64 00 0c c2 09 24 0c 00 00 10 09 40 00 09 40 39 01 00 00 00 00 0c c2 09 24 0c 00 00 10 00 00 00 09 40 39 01 00 00 00 00 4a c1 94 42 00 16 05 00 00 00 10 00 10 00 aa 8a 02 10 00 10 00 00 3f 3f 03 ff 03 ff 23 ff 03 ff 23 ff 03 ff 00 40 40 00 00 10 06 00 06 00 00 00 10 00 00 00 00 10 00 00 00 00 10 00 00 20 02 10 01 10 00 00 00 00 00 20 04 20 02 39 01 00 00 00 00 35 d3 49 00 00 01 1a 15 00 15 07 0f 77 77 77 37 b2 11 00 a0 3c 9a 00 3e 6a 10 60 10 01 03 73 07 ff 04 44 33 33 83 04 00 00 00 00 00 00 00 3c 00 7e 7e 7e 00 42 01 39 01 00 00 00 00 1a d7 00 b9 40 00 40 04 00 f0 0f 00 40 00 00 00 00 00 00 19 40 00 40 04 00 f0 0f 39 01 00 00 00 00 3c d8 00 00 00 00 00 00 00 00 00 3a 00 3a 00 3a 00 3a 00 3a 05 00 00 00 00 00 00 00 00 00 0f 00 0f 00 00 00 00 00 00 00 00 00 00 00 00 00 0f 00 2f 00 0f 00 20 00 00 00 00 00 00 00 00];
				qcom,mdss-dsi-lp1-command = [39 01 00 00 14 00 02 53 04 39 01 00 00 00 00 02 b0 80 39 01 00 00 14 00 02 df b4 39 01 00 00 00 00 02 39 00 39 01 00 00 00 00 02 b0 04 39 01 00 00 00 00 03 e8 00 02 39 01 00 00 00 00 03 e4 00 34 39 01 00 00 00 00 02 b0 04 39 01 00 00 00 00 7d c1 d4 42 00 3f 0f 00 00 00 10 00 10 00 aa 8a 02 10 00 10 00 00 3f 3f 03 ff 03 ff 23 ff 03 ff 23 ff 03 ff f0 40 40 00 00 10 06 00 06 00 00 00 10 00 00 00 00 10 00 00 00 00 10 00 00 20 02 10 01 10 00 00 00 00 00 20 04 20 03 10 00 00 00 00 00 00 00 10 00 00 00 00 00 00 00 00 00 10 00 00 00 00 00 00 00 00 00 00 00 00 00 00 00 00 00 00 00 00 00 00 00 00 00 00 00 00 00 00 00 00 39 01 00 00 00 00 35 d3 45 00 00 01 13 15 00 15 07 0f 77 77 77 37 b2 11 00 a0 3c 9c 00 3e 6a 10 60 10 01 03 73 01 11 01 11 33 33 83 04 00 00 00 00 00 00 00 3c 00 7e 7e 7e 03 42 01 39 01 00 00 00 00 1a d7 00 b9 40 00 40 00 02 c0 2c 00 40 00 00 00 00 00 00 19 40 00 00 00 02 c0 2c 39 01 00 00 00 00 3c d8 00 00 00 00 00 00 00 00 00 5b 00 5b 00 5b 00 5b 00 5b 05 00 00 00 00 00 00 00 00 00 2c 00 2c 00 00 00 00 00 00 00 00 00 00 00 00 00 2c 00 6d 00 2c 00 0c 00 00 00 00 00 00 00 00];
				qcom,mdss-dsi-nolp-command-state = "dsi_hs_mode";
				qcom,mdss-dsi-lp1-command-state = "dsi_hs_mode";
				nubia,mdss-dsi-hbm-command-on = [39 01 00 00 00 00 02 b0 00 15 01 00 00 00 00 02 53 e8];
				nubia,mdss-dsi-hbm-command-off = [39 01 00 00 00 00 02 b0 00 15 01 00 00 00 00 02 53 00];
				nubia,mdss-dsi-hbm-fp-command-on = [39 01 00 00 00 00 02 b0 00 15 01 00 00 00 00 02 53 e0];
				nubia,mdss-dsi-hbm-fp-command-off = [39 01 00 00 00 00 02 b0 00 15 01 00 00 00 00 02 53 00];
				nubia,mdss-dsi-hbm-command-on-state = "dsi_hs_mode";
				nubia,mdss-dsi-hbm-command-off-state = "dsi_hs_mode";
				nubia,mdss-dsi-hbm-fp-command-on-state = "dsi_hs_mode";
				nubia,mdss-dsi-hbm-fp-command-off-state = "dsi_hs_mode";
				qcom,mdss-dsi-h-sync-pulse = <0x0>;
				qcom,compression-mode = "dsc";
				qcom,mdss-dsc-slice-height = <0x14>;
				qcom,mdss-dsc-slice-width = <0x21c>;
				qcom,mdss-dsc-slice-per-pkt = <0x2>;
				qcom,mdss-dsc-bit-per-component = <0x8>;
				qcom,mdss-dsc-bit-per-pixel = <0x8>;
				qcom,mdss-dsc-block-prediction-enable;
				qcom,mdss-dsi-panel-phy-timings = [00 1c 07 07 23 22 07 07 05 02 04 00 18 17];
				qcom,display-topology = <0x1 0x1 0x1>;
				qcom,default-topology-index = <0x0>;
			};

			timing@3 {
				qcom,mdss-dsi-panel-framerate = <0x90>;
				qcom,mdss-dsi-panel-width = <0x438>;
				qcom,mdss-dsi-panel-height = <0x924>;
				qcom,mdss-dsi-h-front-porch = <0x55>;
				qcom,mdss-dsi-h-back-porch = <0x23>;
				qcom,mdss-dsi-h-pulse-width = <0x1>;
				qcom,mdss-dsi-h-sync-skew = <0x0>;
				qcom,mdss-dsi-v-back-porch = <0x4>;
				qcom,mdss-dsi-v-front-porch = <0x18>;
				qcom,mdss-dsi-v-pulse-width = <0x1>;
				qcom,mdss-dsi-h-left-border = <0x0>;
				qcom,mdss-dsi-h-right-border = <0x0>;
				qcom,mdss-dsi-v-top-border = <0x0>;
				qcom,mdss-dsi-v-bottom-border = <0x0>;
				qcom,mdss-mdp-transfer-time-us = <0x17d4>;
				qcom,mdss-dsi-panel-jitter = <0x3c 0xa>;
				qcom,mdss-dsi-on-command = [39 01 00 00 00 00 02 b0 00 39 01 00 00 00 00 02 d1 0b 39 01 00 00 00 00 0c c2 09 24 0c 00 00 10 00 00 00 09 40 39 01 00 00 00 00 2c c4 00 00 00 00 00 00 00 00 10 00 00 02 00 00 00 29 00 01 00 00 00 00 00 00 00 00 00 00 00 22 00 00 00 00 11 00 00 0c 00 00 00 00 30 39 01 00 00 00 00 02 f1 4d 39 01 00 00 00 00 02 cf 13 39 01 00 00 00 00 0d d0 44 44 b2 28 00 28 5a 00 5a 0d 17 01 39 01 00 00 00 00 15 d3 49 00 00 01 b0 15 00 15 07 0f 77 77 77 37 b2 11 00 a0 3c a1 39 01 00 00 00 00 1a d7 00 b9 40 00 40 04 00 f0 0f 00 40 00 00 00 00 00 00 19 40 00 40 04 00 f0 0f 39 01 00 00 00 00 34 d8 00 00 00 00 00 00 00 00 00 30 00 30 00 30 00 30 00 30 05 00 00 00 00 00 00 00 00 00 0f 00 0f 00 00 00 00 00 00 00 00 00 00 00 00 00 0f 00 2f 00 0f 00 20 39 01 00 00 00 00 2b df 50 42 58 81 2d 00 00 00 00 00 00 6b 00 00 00 00 00 00 00 00 01 0f ff d4 0e 00 00 00 00 00 00 0f 53 18 00 0f 00 00 00 00 00 00 39 01 00 00 00 00 02 fa 0b 39 01 00 00 00 00 02 f7 01 39 01 00 00 00 00 02 f1 02 39 01 00 00 00 00 09 c7 00 04 00 00 00 20 00 00 39 01 00 00 00 00 02 f1 32 39 01 00 00 00 00 09 c7 00 04 00 00 00 20 00 00 39 01 00 00 00 00 02 f1 62 39 01 00 00 00 00 09 c7 00 04 00 00 00 20 00 00 39 01 00 00 00 00 02 b0 80 39 01 00 00 00 00 02 f1 24 39 01 00 00 00 00 03 df 51 50 39 01 00 00 00 00 0a e4 34 b4 00 00 00 30 04 0c e2 39 01 00 00 00 00 02 e6 00 39 01 00 00 00 00 02 b0 04 39 01 00 00 00 00 03 df 50 40 39 01 00 00 00 00 06 f3 50 00 00 00 00 39 01 00 00 00 00 02 f2 11 39 01 00 00 00 00 06 f3 01 00 00 00 01 39 01 00 00 00 00 03 f4 00 02 39 01 00 00 00 00 02 f2 19 39 01 00 00 00 00 03 df 50 42 39 01 00 00 00 00 02 35 00 39 01 00 00 00 00 05 2a 00 00 04 37 39 01 00 00 00 00 05 2b 00 00 09 23 05 01 00 00 8c 00 02 11 00 05 01 00 00 14 00 02 29 00];
				qcom,mdss-dsi-timing-switch-command = [39 01 00 00 00 00 02 b0 00 39 01 00 00 00 00 02 d1 0b 39 01 00 00 00 00 0c c2 09 24 0c 00 00 10 00 00 00 09 40 39 01 00 00 00 00 2c c4 00 00 00 00 00 00 00 00 10 00 00 02 00 00 00 29 00 01 00 00 00 00 00 00 00 00 00 00 00 22 00 00 00 00 11 00 00 0c 00 00 00 00 30 39 01 00 00 00 00 02 f1 4d 39 01 00 00 00 00 02 cf 13 39 01 00 00 00 00 0d d0 44 44 b2 28 00 28 5a 00 5a 0d 17 01 39 01 00 00 00 00 15 d3 49 00 00 01 b0 15 00 15 07 0f 77 77 77 37 b2 11 00 a0 3c a1 39 01 00 00 00 00 1a d7 00 b9 40 00 40 04 00 f0 0f 00 40 00 00 00 00 00 00 19 40 00 40 04 00 f0 0f 39 01 00 00 00 00 34 d8 00 00 00 00 00 00 00 00 00 30 00 30 00 30 00 30 00 30 05 00 00 00 00 00 00 00 00 00 0f 00 0f 00 00 00 00 00 00 00 00 00 00 00 00 00 0f 00 2f 00 0f 00 20 39 01 00 00 00 00 02 fa 0b 39 01 00 00 00 00 02 f7 01 39 01 00 00 00 00 02 f1 02 39 01 00 00 00 00 09 c7 00 04 00 00 00 20 00 00 39 01 00 00 00 00 02 f1 32 39 01 00 00 00 00 09 c7 00 04 00 00 00 20 00 00 39 01 00 00 00 00 02 f1 62 39 01 00 00 00 00 09 c7 00 04 00 00 00 20 00 00 39 01 00 00 00 00 02 b0 80 39 01 00 00 00 00 02 f1 24 39 01 00 00 00 00 03 df 51 50 39 01 00 00 00 00 0a e4 34 b4 00 00 00 30 04 0c e2 39 01 00 00 00 00 02 e6 00 39 01 00 00 00 00 02 b0 04 39 01 00 00 00 00 03 df 50 40 39 01 00 00 00 00 06 f3 50 00 00 00 00 39 01 00 00 00 00 02 f2 11 39 01 00 00 00 00 06 f3 01 00 00 00 01 39 01 00 00 00 00 03 f4 00 02 39 01 00 00 00 00 02 f2 19 39 01 00 00 00 00 03 df 50 42 39 01 00 00 00 00 02 35 00 39 01 00 00 00 00 05 2a 00 00 04 37 39 01 00 00 00 00 05 2b 00 00 09 23];
				qcom,mdss-dsi-off-command = [05 01 00 00 64 00 02 28 00 05 01 00 00 32 00 02 10 00];
				qcom,mdss-dsi-on-command-state = "dsi_lp_mode";
				qcom,mdss-dsi-off-command-state = "dsi_hs_mode";
				nubia,mdss-dsi-cabc-command-off = [15 01 00 00 00 00 02 55 00];
				nubia,mdss-dsi-cabc-command-level1 = [15 01 00 00 00 00 02 55 01];
				nubia,mdss-dsi-cabc-command-level2 = [15 01 00 00 00 00 02 55 02];
				nubia,mdss-dsi-cabc-command-level3 = [15 01 00 00 00 00 02 55 03];
				nubia,mdss-dsi-cabc-command-off-state = "dsi_hs_mode";
				nubia,mdss-dsi-cabc-command-level1-state = "dsi_hs_mode";
				nubia,mdss-dsi-cabc-command-level2-state = "dsi_hs_mode";
				nubia,mdss-dsi-cabc-command-level3-state = "dsi_hs_mode";
				qcom,mdss-dsi-nolp-command = [39 01 00 00 00 00 02 b0 80 39 01 00 00 00 00 02 df b4 39 01 00 00 00 00 02 53 04 39 01 00 00 50 00 03 51 00 00 39 01 00 00 00 00 02 38 00 39 01 00 00 00 00 02 b0 04 39 01 00 00 64 00 0c c2 09 24 0c 00 00 10 09 40 00 09 40 39 01 00 00 00 00 0c c2 09 24 0c 00 00 10 00 00 00 09 40 39 01 00 00 00 00 4a c1 94 42 00 16 05 00 00 00 10 00 10 00 aa 8a 02 10 00 10 00 00 3f 3f 03 ff 03 ff 23 ff 03 ff 23 ff 03 ff 00 40 40 00 00 10 06 00 06 00 00 00 10 00 00 00 00 10 00 00 00 00 10 00 00 20 02 10 01 10 00 00 00 00 00 20 04 20 02 39 01 00 00 00 00 35 d3 49 00 00 01 1a 15 00 15 07 0f 77 77 77 37 b2 11 00 a0 3c 9a 00 3e 6a 10 60 10 01 03 73 07 ff 04 44 33 33 83 04 00 00 00 00 00 00 00 3c 00 7e 7e 7e 00 42 01 39 01 00 00 00 00 1a d7 00 b9 40 00 40 04 00 f0 0f 00 40 00 00 00 00 00 00 19 40 00 40 04 00 f0 0f 39 01 00 00 00 00 3c d8 00 00 00 00 00 00 00 00 00 30 00 30 00 30 00 30 00 30 05 00 00 00 00 00 00 00 00 00 0f 00 0f 00 00 00 00 00 00 00 00 00 00 00 00 00 0f 00 2f 00 0f 00 20 00 00 00 00 00 00 00 00];
				qcom,mdss-dsi-lp1-command = [39 01 00 00 14 00 02 53 04 39 01 00 00 00 00 02 b0 80 39 01 00 00 14 00 02 df b4 39 01 00 00 00 00 02 39 00 39 01 00 00 00 00 02 b0 04 39 01 00 00 00 00 03 e8 00 02 39 01 00 00 00 00 03 e4 00 34 39 01 00 00 00 00 02 b0 04 39 01 00 00 00 00 7d c1 d4 42 00 3f 0f 00 00 00 10 00 10 00 aa 8a 02 10 00 10 00 00 3f 3f 03 ff 03 ff 23 ff 03 ff 23 ff 03 ff f0 40 40 00 00 10 06 00 06 00 00 00 10 00 00 00 00 10 00 00 00 00 10 00 00 20 02 10 01 10 00 00 00 00 00 20 04 20 03 10 00 00 00 00 00 00 00 10 00 00 00 00 00 00 00 00 00 10 00 00 00 00 00 00 00 00 00 00 00 00 00 00 00 00 00 00 00 00 00 00 00 00 00 00 00 00 00 00 00 00 39 01 00 00 00 00 35 d3 45 00 00 01 13 15 00 15 07 0f 77 77 77 37 b2 11 00 a0 3c 9c 00 3e 6a 10 60 10 01 03 73 01 11 01 11 33 33 83 04 00 00 00 00 00 00 00 3c 00 7e 7e 7e 03 42 01 39 01 00 00 00 00 1a d7 00 b9 40 00 40 00 02 c0 2c 00 40 00 00 00 00 00 00 19 40 00 00 00 02 c0 2c 39 01 00 00 00 00 3c d8 00 00 00 00 00 00 00 00 00 5b 00 5b 00 5b 00 5b 00 5b 05 00 00 00 00 00 00 00 00 00 2c 00 2c 00 00 00 00 00 00 00 00 00 00 00 00 00 2c 00 6d 00 2c 00 0c 00 00 00 00 00 00 00 00];
				qcom,mdss-dsi-nolp-command-state = "dsi_hs_mode";
				qcom,mdss-dsi-lp1-command-state = "dsi_hs_mode";
				nubia,mdss-dsi-hbm-command-on = [39 01 00 00 00 00 02 b0 00 15 01 00 00 00 00 02 53 e8];
				nubia,mdss-dsi-hbm-command-off = [39 01 00 00 00 00 02 b0 00 15 01 00 00 00 00 02 53 00];
				nubia,mdss-dsi-hbm-fp-command-on = [39 01 00 00 00 00 02 b0 00 15 01 00 00 00 00 02 53 e0];
				nubia,mdss-dsi-hbm-fp-command-off = [39 01 00 00 00 00 02 b0 00 15 01 00 00 00 00 02 53 00];
				nubia,mdss-dsi-hbm-command-on-state = "dsi_hs_mode";
				nubia,mdss-dsi-hbm-command-off-state = "dsi_hs_mode";
				nubia,mdss-dsi-hbm-fp-command-on-state = "dsi_hs_mode";
				nubia,mdss-dsi-hbm-fp-command-off-state = "dsi_hs_mode";
				qcom,mdss-dsi-h-sync-pulse = <0x0>;
				qcom,compression-mode = "dsc";
				qcom,mdss-dsc-slice-height = <0x14>;
				qcom,mdss-dsc-slice-width = <0x21c>;
				qcom,mdss-dsc-slice-per-pkt = <0x2>;
				qcom,mdss-dsc-bit-per-component = <0x8>;
				qcom,mdss-dsc-bit-per-pixel = <0x8>;
				qcom,mdss-dsc-block-prediction-enable;
				qcom,mdss-dsi-panel-phy-timings = [00 21 08 08 25 23 09 08 06 02 04 00 1b 18];
				qcom,display-topology = <0x1 0x1 0x1>;
				qcom,default-topology-index = <0x0>;
			};
		};
	};
};
